# io96b_user_mailbox: IP-XACT component
VLNV Vendor:Library:io96b_user_mailbox:1.0

## Bus interfaces (logical=physical port)
io96b_user_mailbox_slave: slave Magillem:MRV:MRVBusDef:1.0, memory map io96b_user_mailbox
  parameters _mre_definition_=io96b_user_mailbox

## Address spaces and blocks
io96b_user_mailbox.io96b_user_mailbox_block: base 0x0, range 0x460, width 32, register

## Registers
Registers are 32-bit, read-write, reset 0x0 unless marked. A register's access mark holds for its fields unless they carry their own. Offsets are from the block's base; lines under a group give offsets from that group; [hi:lo] are bit positions; {n}, {i} and the like mark numbered series; 'fields as' and 'values as' point back to an identical list; <NAME> marks a mode.

## io96b_user_mailbox.io96b_user_mailbox_block
Base 0x00000000
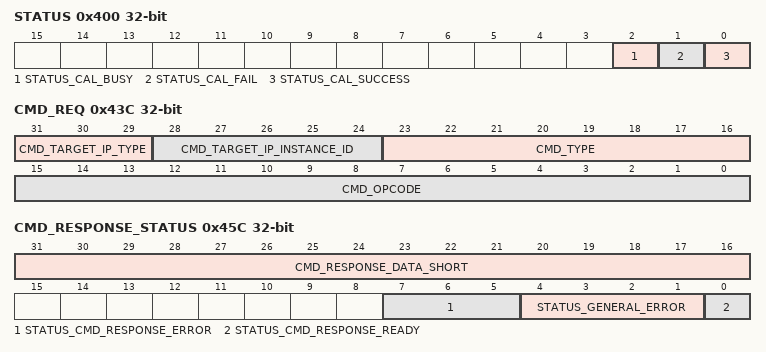
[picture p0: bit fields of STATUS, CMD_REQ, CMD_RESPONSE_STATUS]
0x400 STATUS — <b>Status </b>
  [2] STATUS_CAL_BUSY — <b>Indicates calibration busy status of any external memory interfaces in the IO96: </b><p> '1' - One or more EMIF instances are busy with calibration. '0' - No EMIF instances are busy with calibration. </p>
  [1] STATUS_CAL_FAIL — <b>Indicates calibration failure status of any external memory interfaces in the IO96: </b><p> '1' - One or more EMIF instances have failed to calibrate successfully </p><p> '0' - No calibration failures have been reported for any of the EMIFs. </p>
  [0] STATUS_CAL_SUCCESS — <b>Indicates final calibration status of all interfaces in the IO96: </b><p> '1' All EMIF instances within the IO96 have calibrated successfully </p><p> '0' One or more EMIF instances in the IO96 have either failed to calibrate or have not completed calibration yet. </p>
0x420 CMD_PARAM_6 — <b>Command Request Parameter 6 </b>
  [31:0] CMD_PARAM_6 — <b>This register specifies the seventh parameter (if applicable) for the requested command. </b>
0x424 CMD_PARAM_5 — <b>Command Request Parameter 5 </b>
  [31:0] CMD_PARAM_5 — <b>This register specifies the sixth parameter (if applicable) for the requested command. </b>
0x428 CMD_PARAM_4 — <b>Command Request Parameter 4 </b>
  [31:0] CMD_PARAM_4 — <b>This register specifies the fifth parameter (if applicable) for the requested command. </b>
0x42C CMD_PARAM_3 — <b>Command Request Parameter 3 </b>
  [31:0] CMD_PARAM_3 — <b>This register specifies the fourth parameter (if applicable) for the requested command. </b>
0x430 CMD_PARAM_2 — <b>Command Request Parameter 2 </b>
  [31:0] CMD_PARAM_2 — <b>This register specifies the third parameter (if applicable) for the requested command. </b>
0x434 CMD_PARAM_1 — <b>Command Request Parameter 1 </b>
  [31:0] CMD_PARAM_1 — <b>This register specifies the second parameter (if applicable) for the requested command. </b>
0x438 CMD_PARAM_0 — <b>Command Request Parameter 0 </b>
  [31:0] CMD_PARAM_0 — <b>This register specifies the first parameter (if applicable) for the requested command. </b>
0x43C CMD_REQ — <b>Command Request </b>
  [31:29] CMD_TARGET_IP_TYPE — <b>Indicates the type of IP: </b><p> 0x0 Not used, 0x1 EMIF </p>
  [28:24] CMD_TARGET_IP_INSTANCE_ID — <b>Indicates the USER ID of the user claiming the interface </b>
  [23:16] CMD_TYPE — <b>The type of the command that the user wishes for firmware to perform. </b>
  [15:0] CMD_OPCODE — <b>The opcode of the command that the user wishes for firmware to perform </b>
0x450 CMD_RESPONSE_DATA_2 — <b>Command Response Data 2 </b>
  [31:0] CMD_RESPONSE_DATA_2 — <b> For commands that return up to 3.5x 32-bit values, CMD_RESPONSE_DATA 0/1/2, and/or CMD_RESPONSE_DATA_SHORT fields contain the requested response data. </b>
0x454 CMD_RESPONSE_DATA_1 — <b>Command Response Data 1 </b>
  [31:0] CMD_RESPONSE_DATA_1 — <b> This register can contain two types of values depending on the requested operation. For commands that return up to 3.5x 32-bit values, CMD_RESPONSE_DATA 0/1/2, and/or CMD_RESPONSE_DATA_SHORT fields contain the requested response data. For commands that return more data, this register specifies a pointer to a data buffer within the 4K User. It is a byte offset relative to the start of the 4Kbyte RAM. Users should not assume that this offset value remains static as the value of this pointer offset may change depending on the requested operation. </b>
0x458 CMD_RESPONSE_DATA_0 — <b>Command Response Data 0 </b>
  [31:0] CMD_RESPONSE_DATA_0 — <b> This register can contain two types of values depending on the requested operation. For commands that return up to 3.5x 32-bit values, CMD_RESPONSE_DATA 0/1/2, and/or CMD_RESPONSE_DATA_SHORT fields contain the requested response data. For commands that return more data, this value contains the size of the returned data structure in bytes. The location of the data buffer is specified in CMD_RESPONSE_DATA_1. </b>
0x45C CMD_RESPONSE_STATUS — <b>Command Response status </b>
  [31:16] CMD_RESPONSE_DATA_SHORT — <b>For commands that return up to 16-bit value, this field contains the requested response data. </b>
  [7:5] STATUS_CMD_RESPONSE_ERROR — <b>Reports errors related to the specific command </b><p>'000' - No error, other errors will be mentioned along with the specific command</p>
  [4:1] STATUS_GENERAL_ERROR — <b> Reports general errors </b> <p>'0000' - No error, '0001 - Indicates that an illegal command was received, '0010' - Indicates that the interface the command is targetting doesn't exist</p>
  [0] STATUS_CMD_RESPONSE_READY — <b>Tells whether the command response is ready </b><p>'1' - The response is ready </p>
